# ETHCAT register map
Registers are 8-bit, read-only, no defined reset value unless marked. A register's access mark holds for its fields unless they carry their own. Addresses are absolute; registers are grouped by the start of their names; [hi:lo] are bit positions; {n}, {i} and the like mark numbered series.

## FMMU6
0x44010660 FMMU6_L_START_ADR 32-bit
  [31:0] LSTAADR
0x44010664 FMMU6_LEN 16-bit
  [15:0] FMMULEN
0x44010666 FMMU6_L_START_BIT
  [2:0] LSTABIT
0x44010667 FMMU6_L_STOP_BIT
  [2:0] LSTPBIT
0x44010668 FMMU6_P_START_ADR 16-bit
  [15:0] PHYSTAADR
0x4401066A FMMU6_P_START_BIT
  [2:0] PHYSTABIT
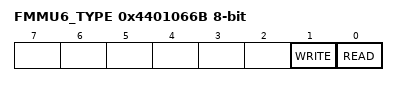
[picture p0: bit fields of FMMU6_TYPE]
0x4401066B FMMU6_TYPE
  [1] WRITE, [0] READ
0x4401066C FMMU6_ACT
  [0] ACTIVATE

## FMMU7
0x44010670 FMMU7_L_START_ADR 32-bit
  [31:0] LSTAADR
0x44010674 FMMU7_LEN 16-bit
  [15:0] FMMULEN
0x44010676 FMMU7_L_START_BIT
  [2:0] LSTABIT
0x44010677 FMMU7_L_STOP_BIT
  [2:0] LSTPBIT
0x44010678 FMMU7_P_START_ADR 16-bit
  [15:0] PHYSTAADR
0x4401067A FMMU7_P_START_BIT
  [2:0] PHYSTABIT
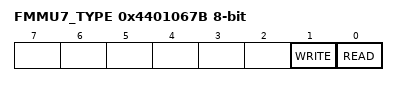
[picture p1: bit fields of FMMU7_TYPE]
0x4401067B FMMU7_TYPE
  [1] WRITE, [0] READ
0x4401067C FMMU7_ACT
  [0] ACTIVATE

## SM0
0x44010800 SM0_P_START_ADR 16-bit
  [15:0] SMSTAADDR
0x44010802 SM0_LEN 16-bit
  [15:0] SMLEN
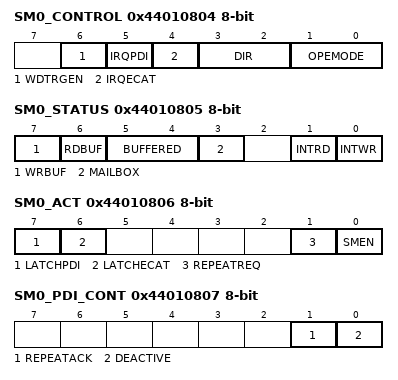
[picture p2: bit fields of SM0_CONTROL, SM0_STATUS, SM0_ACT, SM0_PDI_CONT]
0x44010804 SM0_CONTROL
  [6] WDTRGEN, [5] IRQPDI, [4] IRQECAT, [3:2] DIR, [1:0] OPEMODE
0x44010805 SM0_STATUS
  [7] WRBUF, [6] RDBUF, [5:4] BUFFERED, [3] MAILBOX, [1] INTRD, [0] INTWR
0x44010806 SM0_ACT
  [7] LATCHPDI, [6] LATCHECAT, [1] REPEATREQ, [0] SMEN
0x44010807 SM0_PDI_CONT access not given
  [1] REPEATACK, [0] DEACTIVE

## SM1
0x44010808 SM1_P_START_ADR 16-bit
  [15:0] SMSTAADDR
0x4401080A SM1_LEN 16-bit
  [15:0] SMLEN
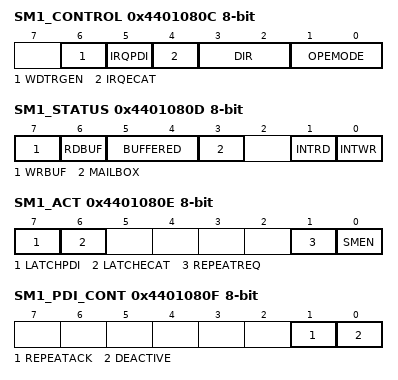
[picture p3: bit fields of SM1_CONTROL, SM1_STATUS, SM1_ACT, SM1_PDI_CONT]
0x4401080C SM1_CONTROL
  [6] WDTRGEN, [5] IRQPDI, [4] IRQECAT, [3:2] DIR, [1:0] OPEMODE
0x4401080D SM1_STATUS
  [7] WRBUF, [6] RDBUF, [5:4] BUFFERED, [3] MAILBOX, [1] INTRD, [0] INTWR
0x4401080E SM1_ACT
  [7] LATCHPDI, [6] LATCHECAT, [1] REPEATREQ, [0] SMEN
0x4401080F SM1_PDI_CONT access not given
  [1] REPEATACK, [0] DEACTIVE

## SM2
0x44010810 SM2_P_START_ADR 16-bit
  [15:0] SMSTAADDR
0x44010812 SM2_LEN 16-bit
  [15:0] SMLEN
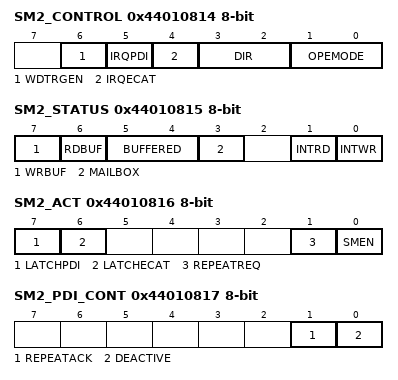
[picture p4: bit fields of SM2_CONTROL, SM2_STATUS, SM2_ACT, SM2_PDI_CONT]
0x44010814 SM2_CONTROL
  [6] WDTRGEN, [5] IRQPDI, [4] IRQECAT, [3:2] DIR, [1:0] OPEMODE
0x44010815 SM2_STATUS
  [7] WRBUF, [6] RDBUF, [5:4] BUFFERED, [3] MAILBOX, [1] INTRD, [0] INTWR
0x44010816 SM2_ACT
  [7] LATCHPDI, [6] LATCHECAT, [1] REPEATREQ, [0] SMEN
0x44010817 SM2_PDI_CONT access not given
  [1] REPEATACK, [0] DEACTIVE

## SM3
0x44010818 SM3_P_START_ADR 16-bit
  [15:0] SMSTAADDR
0x4401081A SM3_LEN 16-bit
  [15:0] SMLEN
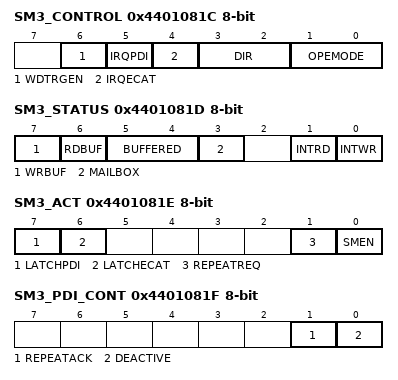
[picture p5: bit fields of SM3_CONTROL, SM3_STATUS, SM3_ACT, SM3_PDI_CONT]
0x4401081C SM3_CONTROL
  [6] WDTRGEN, [5] IRQPDI, [4] IRQECAT, [3:2] DIR, [1:0] OPEMODE
0x4401081D SM3_STATUS
  [7] WRBUF, [6] RDBUF, [5:4] BUFFERED, [3] MAILBOX, [1] INTRD, [0] INTWR
0x4401081E SM3_ACT
  [7] LATCHPDI, [6] LATCHECAT, [1] REPEATREQ, [0] SMEN
0x4401081F SM3_PDI_CONT access not given
  [1] REPEATACK, [0] DEACTIVE

## SM4
0x44010820 SM4_P_START_ADR 16-bit
  [15:0] SMSTAADDR
0x44010822 SM4_LEN 16-bit
  [15:0] SMLEN
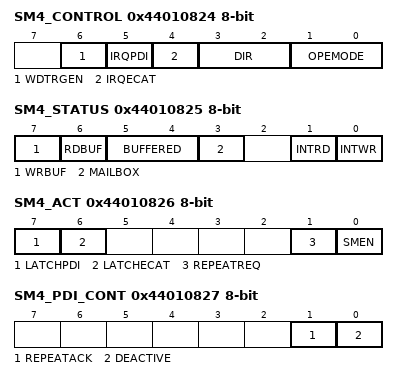
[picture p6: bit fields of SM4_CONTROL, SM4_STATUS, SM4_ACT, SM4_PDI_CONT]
0x44010824 SM4_CONTROL
  [6] WDTRGEN, [5] IRQPDI, [4] IRQECAT, [3:2] DIR, [1:0] OPEMODE
0x44010825 SM4_STATUS
  [7] WRBUF, [6] RDBUF, [5:4] BUFFERED, [3] MAILBOX, [1] INTRD, [0] INTWR
0x44010826 SM4_ACT
  [7] LATCHPDI, [6] LATCHECAT, [1] REPEATREQ, [0] SMEN
0x44010827 SM4_PDI_CONT access not given
  [1] REPEATACK, [0] DEACTIVE

## SM5
0x44010828 SM5_P_START_ADR 16-bit
  [15:0] SMSTAADDR
0x4401082A SM5_LEN 16-bit
  [15:0] SMLEN
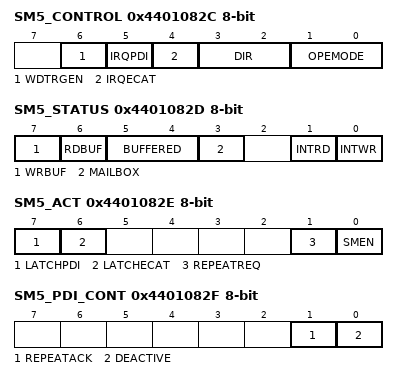
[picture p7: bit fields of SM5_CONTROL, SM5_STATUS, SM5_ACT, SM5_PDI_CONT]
0x4401082C SM5_CONTROL
  [6] WDTRGEN, [5] IRQPDI, [4] IRQECAT, [3:2] DIR, [1:0] OPEMODE
0x4401082D SM5_STATUS
  [7] WRBUF, [6] RDBUF, [5:4] BUFFERED, [3] MAILBOX, [1] INTRD, [0] INTWR
0x4401082E SM5_ACT
  [7] LATCHPDI, [6] LATCHECAT, [1] REPEATREQ, [0] SMEN
0x4401082F SM5_PDI_CONT access not given
  [1] REPEATACK, [0] DEACTIVE

## SM6
0x44010830 SM6_P_START_ADR 16-bit
  [15:0] SMSTAADDR
0x44010832 SM6_LEN 16-bit
  [15:0] SMLEN
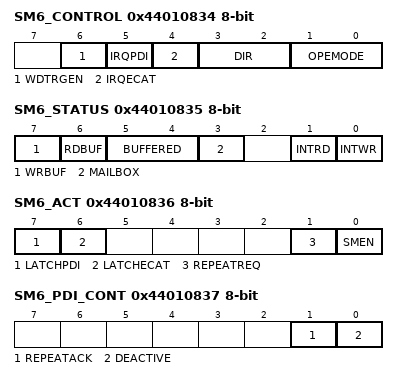
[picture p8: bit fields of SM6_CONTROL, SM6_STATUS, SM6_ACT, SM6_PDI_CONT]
0x44010834 SM6_CONTROL
  [6] WDTRGEN, [5] IRQPDI, [4] IRQECAT, [3:2] DIR, [1:0] OPEMODE
0x44010835 SM6_STATUS
  [7] WRBUF, [6] RDBUF, [5:4] BUFFERED, [3] MAILBOX, [1] INTRD, [0] INTWR
0x44010836 SM6_ACT
  [7] LATCHPDI, [6] LATCHECAT, [1] REPEATREQ, [0] SMEN
0x44010837 SM6_PDI_CONT access not given
  [1] REPEATACK, [0] DEACTIVE

## SM7
0x44010838 SM7_P_START_ADR 16-bit
  [15:0] SMSTAADDR
0x4401083A SM7_LEN 16-bit
  [15:0] SMLEN
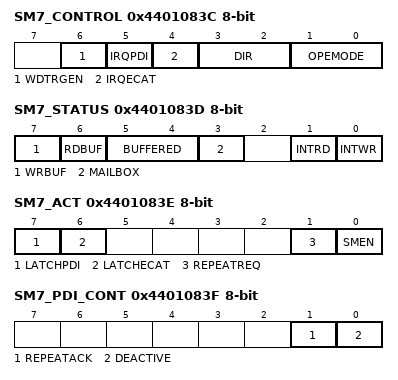
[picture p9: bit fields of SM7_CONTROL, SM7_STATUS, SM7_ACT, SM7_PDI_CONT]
0x4401083C SM7_CONTROL
  [6] WDTRGEN, [5] IRQPDI, [4] IRQECAT, [3:2] DIR, [1:0] OPEMODE
0x4401083D SM7_STATUS
  [7] WRBUF, [6] RDBUF, [5:4] BUFFERED, [3] MAILBOX, [1] INTRD, [0] INTWR
0x4401083E SM7_ACT
  [7] LATCHPDI, [6] LATCHECAT, [1] REPEATREQ, [0] SMEN
0x4401083F SM7_PDI_CONT access not given
  [1] REPEATACK, [0] DEACTIVE

## DC
{0x44010900+4i} DC_RCV_TIME_PORT{i} 32-bit (i=0..2)
  [31:0] RCVTIME{i}
0x44010910 DC_SYS_TIME 64-bit
  [63:0] SYSTIME
0x44010918 DC_RCV_TIME_UNIT 64-bit
  [63:0] RCVTIMEEPU
0x44010920 DC_SYS_TIME_OFFSET 64-bit
  [63:0] SYSTIMOFST
0x44010928 DC_SYS_TIME_DELAY 32-bit
  [31:0] SYSTIMDLY
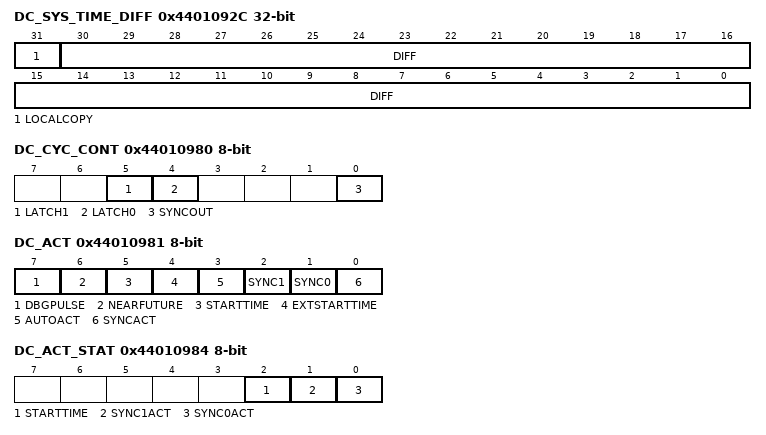
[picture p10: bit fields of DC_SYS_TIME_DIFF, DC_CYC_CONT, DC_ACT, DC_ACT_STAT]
0x4401092C DC_SYS_TIME_DIFF 32-bit
  [31] LOCALCOPY, [30:0] DIFF
0x44010930 DC_SPEED_COUNT_START 16-bit
  [14:0] SPDCNTSTRT
0x44010932 DC_SPEED_COUNT_DIFF 16-bit
  [15:0] SPDCNTDIFF
0x44010934 DC_SYS_TIME_DIFF_FIL_DEPTH
  [3:0] SYSTIMDEP
0x44010935 DC_SPEED_COUNT_FIL_DEPTH
  [3:0] CLKPERDEP
0x44010980 DC_CYC_CONT
  [5] LATCH1, [4] LATCH0, [0] SYNCOUT
0x44010981 DC_ACT access not given
  [7] DBGPULSE, [6] NEARFUTURE, [5] STARTTIME, [4] EXTSTARTTIME, [3] AUTOACT, [2] SYNC1, [1] SYNC0, [0] SYNCACT
0x44010982 DC_PULSE_LEN 16-bit
  [15:0] PULSELEN
0x44010984 DC_ACT_STAT
  [2] STARTTIME, [1] SYNC1ACT, [0] SYNC0ACT
0x4401098E DC_SYNC0_STAT
  [0] SYNC0STA
0x4401098F DC_SYNC1_STAT
  [0] SYNC1STA
0x44010990 DC_CYC_START_TIME 64-bit access not given
  [63:0] STATIM
0x44010998 DC_NEXT_SYNC1_PULSE 64-bit
  [63:0] SYNC1PULSE
0x440109A0 DC_SYNC0_CYC_TIME 32-bit access not given
  [31:0] SYNC0CYC
0x440109A4 DC_SYNC1_CYC_TIME 32-bit access not given
  [31:0] SYNC1CYC
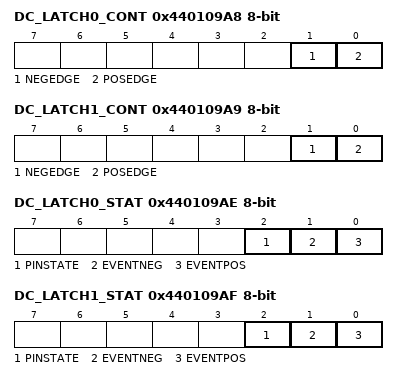
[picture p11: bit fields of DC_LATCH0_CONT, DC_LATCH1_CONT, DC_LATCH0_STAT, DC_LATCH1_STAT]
0x440109A8 DC_LATCH0_CONT access not given
  [1] NEGEDGE, [0] POSEDGE
0x440109A9 DC_LATCH1_CONT access not given
  [1] NEGEDGE, [0] POSEDGE
0x440109AE DC_LATCH0_STAT
  [2] PINSTATE, [1] EVENTNEG, [0] EVENTPOS
0x440109AF DC_LATCH1_STAT
  [2] PINSTATE, [1] EVENTNEG, [0] EVENTPOS
0x440109B0 DC_LATCH0_TIME_POS 64-bit
  [63:0] SYSTIME
0x440109B8 DC_LATCH0_TIME_NEG 64-bit
  [63:0] SYSTIME
0x440109C0 DC_LATCH1_TIME_POS 64-bit
  [63:0] SYSTIME
0x440109C8 DC_LATCH1_TIME_NEG 64-bit
  [63:0] SYSTIME
0x440109F0 DC_ECAT_CNG_EV_TIME 32-bit
  [31:0] ECATCHANGE
0x440109F8 DC_PDI_START_EV_TIME 32-bit
  [31:0] PDISTART
0x440109FC DC_PDI_CNG_EV_TIME 32-bit
  [31:0] PDICHANGE
